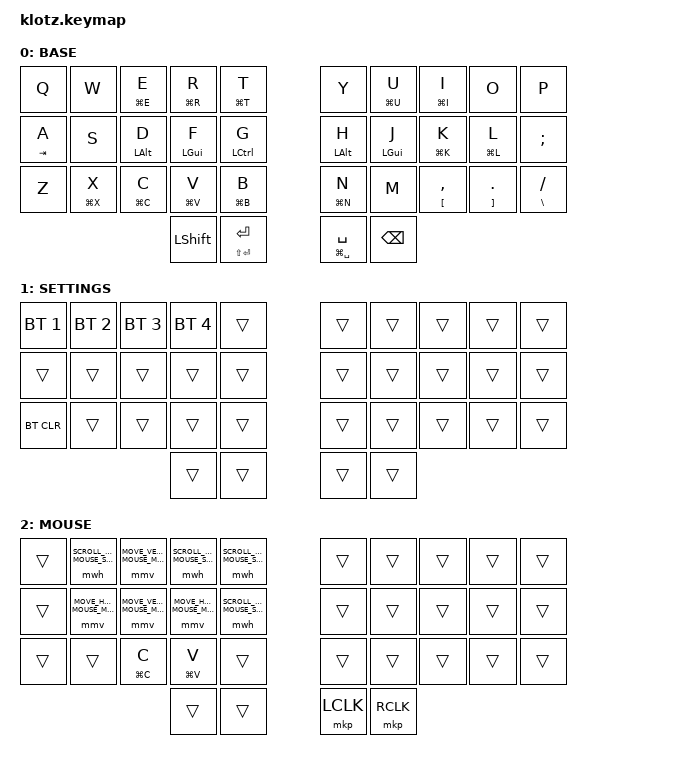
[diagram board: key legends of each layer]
//                                      █         ██        ▄▀▀▀▀▀▀▀▀▀▀█▀▀▀▀▀▀▀▀█▀▀▀▀▀▀▀▀▀▀█
//                                      █        █ █      ▄▀            ▀▄      █         █
//                                      █       █  █    ▄▀                ▀▄    █        █
//                                      █      █   █   █                    █   █       █
//                                      █     █    █   █                    █   █      █
//                                      █    █     █   █                    █   █  ▀▀▀█▀▀▀▀
//                                      █   █ █    █   █                    █   █    █
//                                      █  █   █   █   █                    █   █   █
//                                      █ █     █  █    ▀▄                ▄▀    █  █
//                                      ██       █ █      ▀▄            ▄▀      █ █
//                                      █         ██▄▄▄▄▄▄▄▄█▄▄▄▄▄▄▄▄▄▄▀        ██▄▄▄▄▄▄▄▄▄▄
//
// ▄▄▄▄▄▄▄▄▄▄▄▄▄▄▄▄▄▄▄▄▄▄▄▄▄▄▄▄▄▄▄▄▄▄▄▄▄▄▄▄▄▄▄▄▄▄▄▄▄▄▄▄▄▄▄▄▄▄▄▄▄▄▄▄▄▄▄▄▄▄▄▄▄▄▄▄▄▄▄▄▄▄▄▄▄▄▄▄▄▄▄▄▄▄▄▄▄▄▄▄▄▄▄▄▄▄▄▄▄▄▄▄▄▄▄▄▄▄▄▄▄▄▄▄▄

#include <behaviors.dtsi>
#include <dt-bindings/zmk/keys.h>
#include <dt-bindings/zmk/bt.h>
#include <dt-bindings/zmk/mouse.h>

#define BASE 0
#define NAV  1
#define SYM  2
#define ADJ  3
#define TVP1 4
#define TVP2 5
#define U_MOUSE_MOVE_MAX 1400

#undef MOVE_UP
#undef MOVE_DOWN
#undef MOVE_LEFT
#undef MOVE_RIGHT

#define MOVE_UP MOVE_VERT(-U_MOUSE_MOVE_MAX)
#define MOVE_DOWN MOVE_VERT(U_MOUSE_MOVE_MAX)
#define MOVE_LEFT MOVE_HOR(-U_MOUSE_MOVE_MAX)
#define MOVE_RIGHT MOVE_HOR(U_MOUSE_MOVE_MAX)
#define U_MOUSE_SCROLL_MAX 12

#undef SCROLL_UP
#undef SCROLL_DOWN
#undef SCROLL_LEFT
#undef SCROLL_RIGHT

#define SCROLL_UP SCROLL_VERT(U_MOUSE_SCROLL_MAX)
#define SCROLL_DOWN SCROLL_VERT(-U_MOUSE_SCROLL_MAX)
#define SCROLL_LEFT SCROLL_HOR(-U_MOUSE_SCROLL_MAX)
#define SCROLL_RIGHT SCROLL_HOR(U_MOUSE_SCROLL_MAX)

&mmv {
    time-to-max-speed-ms = <250>;
    acceleration-exponent = <1>;
};

&mwh {
    time-to-max-speed-ms = <250>;
    acceleration-exponent = <1>;
};

&mt {
    quick-tap-ms = <100>;
    global-quick-tap;
    flavor = "tap-preferred";
    tapping-term-ms = <200>;
};

/ {
    combos {
        compatible = "zmk,combos";

        combo_esc {
            timeout-ms = <25>;
            key-positions = <0 1>;
            bindings = <&kp ESC>;
        };

        combo_settings {
            timeout-ms = <25>;
            bindings = <&to 1>;
            key-positions = <31 30 24>;
        };

        combo_pp {
            timeout-ms = <25>;
            bindings = <&kp C_PP>;
            key-positions = <4 5>;
        };

        combo_exclamation {
            timeout-ms = <25>;
            bindings = <&kp EXCLAMATION>;
            key-positions = <1 2>;
        };

        combo_AT_SIGN {
            timeout-ms = <25>;
            bindings = <&kp AT>;
            key-positions = <2 3>;
        };

        combo_HASH {
            timeout-ms = <25>;
            bindings = <&kp HASH>;
            key-positions = <1 12>;
        };

        combo_DOLLAR {
            timeout-ms = <25>;
            bindings = <&kp DOLLAR>;
            key-positions = <12 3>;
        };

        combo_PERCENT {
            timeout-ms = <25>;
            bindings = <&kp PERCENT>;
            key-positions = <1 3>;
        };

        combo_CARET {
            timeout-ms = <25>;
            bindings = <&kp CARET>;
            key-positions = <8 6>;
        };

        combo_AMPERSAND {
            timeout-ms = <25>;
            bindings = <&kp AMPERSAND>;
            key-positions = <6 17>;
        };

        combo_ASTERISK {
            timeout-ms = <25>;
            bindings = <&kp ASTERISK>;
            key-positions = <8 17>;
        };

        combo_LEFT_PARENTHESIS {
            timeout-ms = <25>;
            bindings = <&kp LEFT_PARENTHESIS>;
            key-positions = <6 7>;
        };

        combo_RIGHT_PARENTHESIS {
            timeout-ms = <25>;
            bindings = <&kp RIGHT_PARENTHESIS>;
            key-positions = <7 8>;
        };

        combo_VOLUME_UP {
            timeout-ms = <25>;
            bindings = <&kp C_VOLUME_UP>;
            key-positions = <22 23>;
        };

        combo_VOLUME_DOWN {
            timeout-ms = <25>;
            bindings = <&kp C_VOLUME_DOWN>;
            key-positions = <21 20>;
        };

        combo_MUTE {
            timeout-ms = <25>;
            bindings = <&kp C_MUTE>;
            key-positions = <21 22>;
        };

        combo_quote {
            timeout-ms = <30>;
            bindings = <&kp SINGLE_QUOTE>;
            key-positions = <8 9>;
        };

        combo_dash {
            timeout-ms = <30>;
            bindings = <&kp MINUS>;
            key-positions = <18 19>;
        };

        combo_plus {
            timeout-ms = <25>;
            bindings = <&kp PLUS>;
            key-positions = <19 29>;
        };

        combo_multiply {
            timeout-ms = <25>;
            bindings = <&kp ASTERISK>;
            key-positions = <28 19>;
        };

        combo_equal {
            timeout-ms = <25>;
            bindings = <&kp EQUAL>;
            key-positions = <28 29>;
        };

        combo_no1 {
            timeout-ms = <35>;
            bindings = <&kp N1>;
            key-positions = <33 26>;
        };

        combo_no2 {
            timeout-ms = <35>;
            bindings = <&kp N2>;
            key-positions = <33 27>;
        };

        combo_no3 {
            bindings = <&kp N3>;
            key-positions = <33 28>;
        };

        combo_no4 {
            timeout-ms = <35>;
            bindings = <&kp N4>;
            key-positions = <33 16>;
        };

        combo_no5 {
            timeout-ms = <35>;
            bindings = <&kp N5>;
            key-positions = <33 17>;
        };

        combo_no6 {
            timeout-ms = <35>;
            bindings = <&kp N6>;
            key-positions = <33 18>;
        };

        combo_no7 {
            timeout-ms = <35>;
            bindings = <&kp N7>;
            key-positions = <33 6>;
        };

        combo_no8 {
            timeout-ms = <35>;
            bindings = <&kp N8>;
            key-positions = <33 7>;
        };

        combo_no9 {
            timeout-ms = <35>;
            bindings = <&kp N9>;
            key-positions = <33 8>;
        };

        combo_no0 {
            timeout-ms = <35>;
            bindings = <&kp N0>;
            key-positions = <9 33>;
        };

        combo_leftscreen {
            timeout-ms = <30>;
            bindings = <&kp LC(LEFT)>;
            key-positions = <10 0>;
        };

        combo_rightscreen {
            timeout-ms = <30>;
            bindings = <&kp LC(RIGHT)>;
            key-positions = <4 14>;
        };

        combo_nexttrack {
            timeout-ms = <30>;
            bindings = <&kp C_NEXT>;
            key-positions = <21 22 23>;
        };

        combo_prevtrack {
            timeout-ms = <30>;
            bindings = <&kp C_PREV>;
            key-positions = <20 21 22>;
        };

        combo_optleft {
            timeout-ms = <30>;
            bindings = <&kp LA(LEFT)>;
            key-positions = <10 11>;
        };

        combo_optright {
            timeout-ms = <30>;
            bindings = <&kp LA(RIGHT)>;
            key-positions = <14 13>;
        };

        combo_changelang {
            timeout-ms = <35>;
            bindings = <&kp LC(SPACE)>;
            key-positions = <14 13 15 16>;
        };

        combo_up {
            timeout-ms = <30>;
            bindings = <&kp UP>;
            key-positions = <2 12>;
        };

        combo_down {
            timeout-ms = <30>;
            bindings = <&kp DOWN>;
            key-positions = <12 22>;
        };

        combo_left {
            timeout-ms = <30>;
            bindings = <&kp LEFT>;
            key-positions = <11 12>;
        };

        combo_right {
            timeout-ms = <30>;
            bindings = <&kp RIGHT>;
            key-positions = <12 13>;
        };

        combo_spaces {
            timeout-ms = <30>;
            bindings = <&kp LC(UP)>;
            key-positions = <0 4>;
        };

        combo_to0 {
            timeout-ms = <20>;
            bindings = <&to 0>;
            key-positions = <30 31>;
        };

        combo_screenshot {
            timeout-ms = <35>;
            bindings = <&kp LG(LS(N4))>;
            key-positions = <0 20 9 29>;
        };

        combo_cmd_left {
            timeout-ms = <35>;
            bindings = <&kp LG(LEFT)>;
            key-positions = <0 2>;
        };

        combo_cmd_right {
            timeout-ms = <35>;
            bindings = <&kp LG(RIGHT)>;
            key-positions = <2 4>;
        };

        combo_to2 {
            timeout-ms = <20>;
            bindings = <&to 2>;
            key-positions = <32 33>;
        };

        combo_emoji {
            timeout-ms = <20>;
            bindings = <&kp LG(LC(SPACE))>;
            key-positions = <4 5 6 3>;
        };
    };

    macros {
    };

    behaviors {
        gqt: global-quick-tap {
            compatible = "zmk,behavior-hold-tap";
            label = "GLOBAL_QUICK_TAP";
            #binding-cells = <2>;
            flavor = "tap-preferred";
            tapping-term-ms = <250>;
            quick-tap-ms = <125>;
            global-quick-tap;
            bindings =
                <&kp>,
                <&kp>;
        };
    };

    keymap {
        compatible = "zmk,keymap";

        // ▄▄▄▄▄▄▄▄▄▄▄▄▄▄▄▄▄▄▄▄▄▄▄▄▄▄▄▄▄▄▄▄▄▄▄▄▄▄▄▄▄▄▄▄▄▄▄▄▄▄▄▄▄▄▄▄▄▄▄▄▄▄▄▄▄▄▄▄▄▄▄▄▄▄▄▄▄▄▄▄▄▄▄▄▄▄▄▄▄▄▄▄▄▄▄▄▄▄▄▄▄▄▄▄▄▄▄▄▄▄▄▄▄▄▄▄▄▄▄▄▄▄▄▄▄

        BASE {
            // ┏━━━━━━━━━━━━━━━━━━━━━━━━━━━━━━━━━━━━━━━┓

            label = "BASE";

            // ┗━━━━━━━━━━━━━━━━━━━━━━━━━━━━━━━━━━━━━━━┛
            // ┏━━━━━━━━━━━┳━━━━━━━━━━━┳━━━━━━━━━━━┳━━━━━━━━━━━┳━━━━━━━━━━━┓   ┏━━━━━━━━━━━┳━━━━━━━━━━━┳━━━━━━━━━━━┳━━━━━━━━━━━┳━━━━━━━━━━━┓
            // ┃     Q     ┃     W     ┃     F     ┃     P     ┃     G     ┃   ┃     J     ┃     L     ┃     U     ┃     Y     ┃     ;     ┃
            // ┣━━━━━━━━━━━╋━━━━━━━━━━━╋━━━━━━━━━━━╋━━━━━━━━━━━╋━━━━━━━━━━━┫   ┣━━━━━━━━━━━╋━━━━━━━━━━━╋━━━━━━━━━━━╋━━━━━━━━━━━╋━━━━━━━━━━━┫
            // ┃     A     ┃     R     ┃     S     ┃     T     ┃     D     ┃   ┃     H     ┃     N     ┃     E     ┃     I     ┃     O     ┃
            // ┣━━━━━━━━━━━╋━━━━━━━━━━━╋━━━━━━━━━━━╋━━━━━━━━━━━╋━━━━━━━━━━━┫   ┣━━━━━━━━━━━╋━━━━━━━━━━━╋━━━━━━━━━━━╋━━━━━━━━━━━╋━━━━━━━━━━━┫
            // ┃     Z     ┃     X     ┃     C     ┃     V     ┃     B     ┃   ┃     K     ┃     M     ┃     ,     ┃     .     ┃     /     ┃
            // ┗━━━━━━━━━━━┻━━━━━━━━━━━┻━━━━━━━━━━━╋━━━━━━━━━━━╋━━━━━━━━━━━┫   ┣━━━━━━━━━━━╋━━━━━━━━━━━╋━━━━━━━━━━━┻━━━━━━━━━━━┻━━━━━━━━━━━┛
            //                                     ┃    TAB    ┃    SPC    ┃   ┃   ENTER   ┃   BSPC    ┃
            //                                     ┗━━━━━━━━━━━┻━━━━━━━━━━━┛   ┗━━━━━━━━━━━┻━━━━━━━━━━━┛

            bindings = <
      &kp Q         &kp W  &gqt LG(E) E  &gqt LG(R) R          &gqt LG(T) T                 &kp Y   &gqt LG(U) U             &gqt LG(I) I                   &kp O                 &kp P
 &gqt TAB A         &kp S    &mt LALT D    &mt LGUI F           &mt LCTRL G            &mt LALT H     &mt LGUI J             &gqt LG(K) K            &gqt LG(L) L              &kp SEMI
      &kp Z  &gqt LG(X) X  &gqt LG(C) C  &gqt LG(V) V          &gqt LG(B) B          &gqt LG(N) N          &kp M  &gqt LEFT_BRACKET COMMA  &gqt RIGHT_BRACKET DOT  &gqt BACKSLASH SLASH
                                           &kp LSHIFT  &gqt LS(ENTER) ENTER  &gqt LG(SPACE) SPACE  &kp BACKSPACE
            >;

            sensor-bindings = <&inc_dec_kp PAGE_DOWN PAGE_UP>;
        };

        SETTINGS {
            bindings = <
 &bt BT_SEL 1  &bt BT_SEL 2  &bt BT_SEL 3  &bt BT_SEL 4  &trans  &trans  &trans  &trans  &trans  &trans
       &trans        &trans        &trans        &trans  &trans  &trans  &trans  &trans  &trans  &trans
   &bt BT_CLR        &trans        &trans        &trans  &trans  &trans  &trans  &trans  &trans  &trans
                                                 &trans  &trans  &trans  &trans
            >;
        };

        MOUSE {
            bindings = <
 &trans  &mwh SCROLL_HOR(-U_MOUSE_SCROLL_MAX)  &mmv MOVE_VERT(-U_MOUSE_MOVE_MAX)  &mwh SCROLL_HOR(U_MOUSE_SCROLL_MAX)   &mwh SCROLL_VERT(U_MOUSE_SCROLL_MAX)     &trans     &trans  &trans  &trans  &trans
 &trans      &mmv MOVE_HOR(-U_MOUSE_MOVE_MAX)   &mmv MOVE_VERT(U_MOUSE_MOVE_MAX)      &mmv MOVE_HOR(U_MOUSE_MOVE_MAX)  &mwh SCROLL_VERT(-U_MOUSE_SCROLL_MAX)     &trans     &trans  &trans  &trans  &trans
 &trans                                &trans                       &gqt LG(C) C                         &gqt LG(V) V                                 &trans     &trans     &trans  &trans  &trans  &trans
                                                                                                               &trans                                 &trans  &mkp LCLK  &mkp RCLK
            >;
        };

        // ▄▄▄▄▄▄▄▄▄▄▄▄▄▄▄▄▄▄▄▄▄▄▄▄▄▄▄▄▄▄▄▄▄▄▄▄▄▄▄▄▄▄▄▄▄▄▄▄▄▄▄▄▄▄▄▄▄▄▄▄▄▄▄▄▄▄▄▄▄▄▄▄▄▄▄▄▄▄▄▄▄▄▄▄▄▄▄▄▄▄▄▄▄▄▄▄▄▄▄▄▄▄▄▄▄▄▄▄▄▄▄▄▄▄▄▄▄▄▄▄▄▄▄▄▄
        // ▄▄▄▄▄▄▄▄▄▄▄▄▄▄▄▄▄▄▄▄▄▄▄▄▄▄▄▄▄▄▄▄▄▄▄▄▄▄▄▄▄▄▄▄▄▄▄▄▄▄▄▄▄▄▄▄▄▄▄▄▄▄▄▄▄▄▄▄▄▄▄▄▄▄▄▄▄▄▄▄▄▄▄▄▄▄▄▄▄▄▄▄▄▄▄▄▄▄▄▄▄▄▄▄▄▄▄▄▄▄▄▄▄▄▄▄▄▄▄▄▄▄▄▄▄
        // ▄▄▄▄▄▄▄▄▄▄▄▄▄▄▄▄▄▄▄▄▄▄▄▄▄▄▄▄▄▄▄▄▄▄▄▄▄▄▄▄▄▄▄▄▄▄▄▄▄▄▄▄▄▄▄▄▄▄▄▄▄▄▄▄▄▄▄▄▄▄▄▄▄▄▄▄▄▄▄▄▄▄▄▄▄▄▄▄▄▄▄▄▄▄▄▄▄▄▄▄▄▄▄▄▄▄▄▄▄▄▄▄▄▄▄▄▄▄▄▄▄▄▄▄▄
        // ▄▄▄▄▄▄▄▄▄▄▄▄▄▄▄▄▄▄▄▄▄▄▄▄▄▄▄▄▄▄▄▄▄▄▄▄▄▄▄▄▄▄▄▄▄▄▄▄▄▄▄▄▄▄▄▄▄▄▄▄▄▄▄▄▄▄▄▄▄▄▄▄▄▄▄▄▄▄▄▄▄▄▄▄▄▄▄▄▄▄▄▄▄▄▄▄▄▄▄▄▄▄▄▄▄▄▄▄▄▄▄▄▄▄▄▄▄▄▄▄▄▄▄▄▄
        // ▄▄▄▄▄▄▄▄▄▄▄▄▄▄▄▄▄▄▄▄▄▄▄▄▄▄▄▄▄▄▄▄▄▄▄▄▄▄▄▄▄▄▄▄▄▄▄▄▄▄▄▄▄▄▄▄▄▄▄▄▄▄▄▄▄▄▄▄▄▄▄▄▄▄▄▄▄▄▄▄▄▄▄▄▄▄▄▄▄▄▄▄▄▄▄▄▄▄▄▄▄▄▄▄▄▄▄▄▄▄▄▄▄▄▄▄▄▄▄▄▄▄▄▄▄
    };
};
